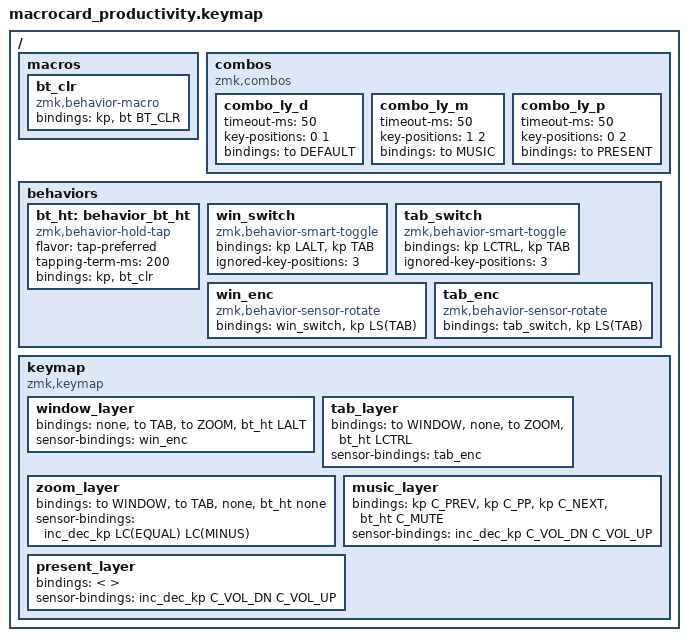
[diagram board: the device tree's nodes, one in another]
#include <behaviors/smart_toggle.dtsi>
#include <dt-bindings/zmk/keys.h>
#include <dt-bindings/zmk/bt.h>
#include <behaviors.dtsi>
#include <dt-bindings/zmk/outputs.h>

#define WINDOW  0
#define TAB     1
#define ZOOM    2
#define MUSIC   3
#define PRESENT 4

/ {
    macros {
        bt_clr: bt_clr {
            compatible = "zmk,behavior-macro";
            #binding-cells = <0>;
            bindings
                = <&kp &bt BT_CLR>;
        };
    };
    combos {
        compatible = "zmk,combos";
        combo_ly_d {
            timeout-ms = <50>;
            key-positions = <0 1>;
            bindings = <&to DEFAULT>;
        };
        combo_ly_m {
            timeout-ms = <50>;
            key-positions = <1 2>;
            bindings = <&to MUSIC>;
        };
        combo_ly_p {
            timeout-ms = <50>;
            key-positions = <0 2>;
            bindings = <&to PRESENT>;
        };
    };
    behaviors {
        bt_ht: behavior_bt_ht {
            compatible = "zmk,behavior-hold-tap";
            #binding-cells = <1>;
            flavor = "tap-preferred";
            tapping-term-ms = <200>;
            bindings = <&kp>, <&bt_clr>;
        };
        // Window switcher behavior using smart toggle
        win_switch: win_switch {
            compatible = "zmk,behavior-smart-toggle";
            #binding-cells = <0>;
            bindings = <&kp LALT>, <&kp TAB>;
            ignored-key-positions = <3>; // Encoder switch position
        };
        
        // Tab switcher behavior using smart toggle
        tab_switch: tab_switch {
            compatible = "zmk,behavior-smart-toggle";
            #binding-cells = <0>;
            bindings = <&kp LCTRL>, <&kp TAB>;
            ignored-key-positions = <3>; // Encoder switch position
        };

        // Window switcher encoder behavior
        win_enc: win_enc {
            compatible = "zmk,behavior-sensor-rotate";
            #sensor-binding-cells = <0>;
            bindings = <&win_switch>, <&kp LS(TAB)>;
        };
        
        // Tab switcher encoder behavior
        tab_enc: tab_enc {
        compatible = "zmk,behavior-sensor-rotate";
            #sensor-binding-cells = <0>;
            bindings = <&tab_switch>, <&kp LS(TAB)>;
        };
    };

    keymap {
        compatible = "zmk,keymap";

        window_layer {
            bindings = <
                &none           // Switch 1 - None
                &to TAB         // Switch 2 - Layer tab
                &to ZOOM        // Switch 3 - Layer zoom
                &bt_ht LALT     // Encoder switch - toggle alt off
            >;
            
            sensor-bindings = <&win_enc>;
        };

        tab_layer {
            bindings = <
                &to WINDOW      // Switch 1 - Layer window
                &none           // Switch 2 - None
                &to ZOOM        // Switch 3 - Layer zoom
                &bt_ht LCTRL    // Encoder switch - toggle ctrl off
            >;
            
            sensor-bindings = <&tab_enc>;
        };

        zoom_layer {
            bindings = <
                &to WINDOW      // Switch 1 - transparent
                &to TAB         // Switch 2 - transparent
                &none           // Switch 3 - transparent
                &bt_ht none     // Encoder switch - hold for BT clear
            >;
            
            sensor-bindings = <&inc_dec_kp LC(EQUAL) LC(MINUS)>;
        };
        music_layer {
            bindings = <
                &kp C_PREV      // Switch 1 - Previous track
                &kp C_PP        // Switch 2 - Play/Pause
                &kp C_NEXT      // Switch 3 - Next track
                &bt_ht C_MUTE   // Encoder switch - tap for mute, hold for BT clear
            >;
            
            sensor-bindings = <&inc_dec_kp C_VOL_DN C_VOL_UP>;
        };
        present_layer {
            bindings = <
                // Add functionality here
            >;
            
            sensor-bindings = <&inc_dec_kp C_VOL_DN C_VOL_UP>;
        };
    };
};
